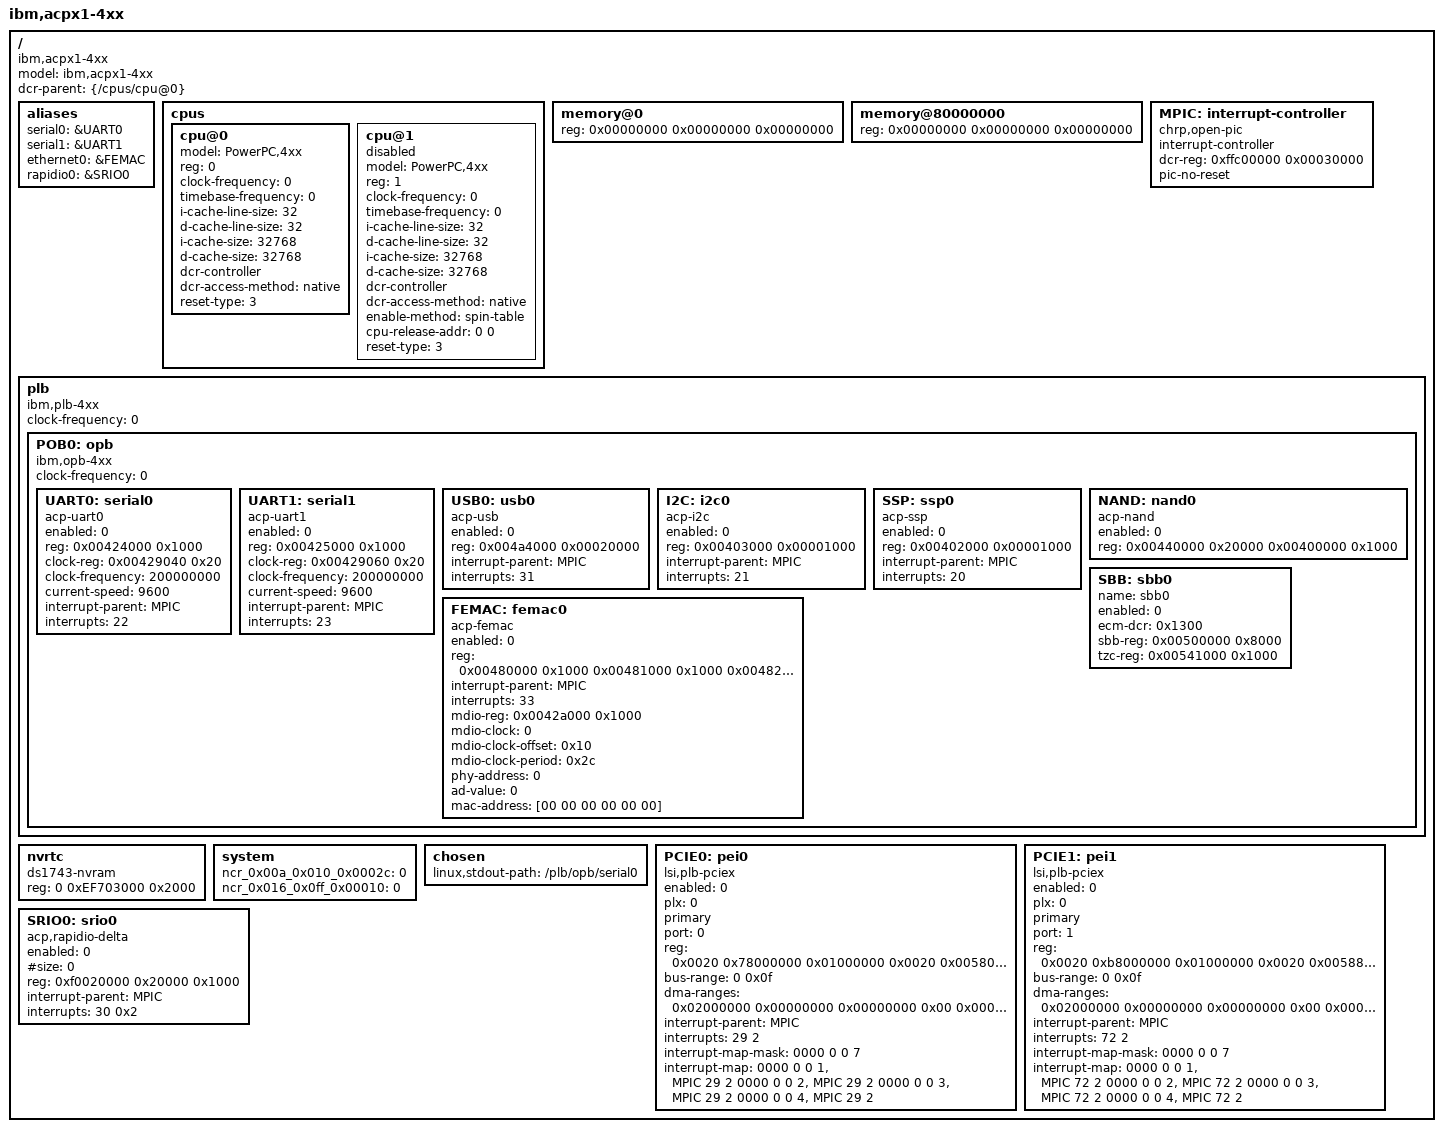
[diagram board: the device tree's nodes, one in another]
/*
 * Device Tree Source for LSI ACP25xx.
 *
 * Copyright 2013, LSI Corporation
 *
 * Based on earlier code:
 *     Copyright (c) 2009, 2006, 2007 IBM Corp.
 *     Josh Boyer <jwboyer@linux.vnet.ibm.com>, David Gibson <dwg@au1.ibm.com>
 *
 * This file is licensed under the terms of the GNU General Public
 * License version 2.  This program is licensed "as is" without
 * any warranty of any kind, whether express or implied.
 */

/dts-v1/;

/memreserve/ 0x00000000 0x00400000;

/ {
	#address-cells = <2>;
	#size-cells = <1>;
	model = "ibm,acpx1-4xx";
	compatible = "ibm,acpx1-4xx","ibm,47x-AMP";
	dcr-parent = <&{/cpus/cpu@0}>;

	aliases {
		serial0   = &UART0;
		serial1   = &UART1;
		ethernet0 = &FEMAC;
		rapidio0  = &SRIO0;
	};

	cpus {
		#address-cells = <1>;
		#size-cells = <0>;

		cpu@0 {
			device_type = "cpu";
			model = "PowerPC,4xx"; // real CPU changed in sim
			reg = <0>;
			clock-frequency = <0>; // filled in by U-Boot
			timebase-frequency = <0>; // filled in by U-Boot
			i-cache-line-size = <32>;
			d-cache-line-size = <32>;
			i-cache-size = <32768>;
			d-cache-size = <32768>;
			dcr-controller;
			dcr-access-method = "native";
			status = "ok";
			reset-type = <3>; // 1=core, 2=chip, 3=system (default)
		};

		cpu@1 {
			device_type = "cpu";
			model = "PowerPC,4xx"; // real CPU changed in sim
			reg = <1>;
			clock-frequency = <0>; // filled in by U-Boot
			timebase-frequency = <0>; // filled in by U-Boot
			i-cache-line-size = <32>;
			d-cache-line-size = <32>;
			i-cache-size = <32768>;
			d-cache-size = <32768>;
			dcr-controller;
			dcr-access-method = "native";
			status = "disabled";
			enable-method = "spin-table";
			cpu-release-addr = <0 0>; // Fixed by the boot loader
			reset-type = <3>; // 1=core, 2=chip, 3=system (default)
		};
	};

        memory@0 {
                device_type = "memory";
                reg = <0x00000000 0x00000000 0x00000000>; // filled in by U-Boot
        };

        memory@80000000 {
                device_type = "memory";
                reg = <0x00000000 0x00000000 0x00000000>; // filled in by U-Boot
        };

	MPIC: interrupt-controller {
		compatible = "chrp,open-pic";
		interrupt-controller;
		dcr-reg = <0xffc00000 0x00030000>;
		#address-cells = <0>;
		#size-cells = <0>;
		#interrupt-cells = <2>;
		pic-no-reset;
	};

	plb {
		/* Could be PLB6, doesn't matter */
		compatible = "ibm,plb-4xx", "ibm,plb4";
		#address-cells = <2>;
		#size-cells = <1>;
		ranges;
		clock-frequency = <0>; // Filled in by zImage

		POB0: opb {
			compatible = "ibm,opb-4xx", "ibm,opb";
			#address-cells = <1>;
			#size-cells = <1>;
			/* Wish there was a nicer way of specifying a full 32-bit
			   range */
			ranges = <0x00000000 0x00000020 0x00000000 0x80000000
				  0x80000000 0x00000020 0x80000000 0x80000000>;
			clock-frequency = <0>; // Filled in by zImage

			UART0: serial0 {
				device_type = "serial";
				compatible = "acp-uart0";
				enabled = <0>;
				reg = <0x00424000 0x1000>;
				clock-reg = <0x00429040 0x20>;
				clock-frequency = <200000000>;
				current-speed = <9600>;
				interrupt-parent = <&MPIC>;
				interrupts = <22>;
				/*interrupts = <23>;*/
			};

			UART1: serial1 {
				device_type = "serial";
				compatible = "acp-uart1";
				enabled = <0>;
				reg = <0x00425000 0x1000>;
				clock-reg = <0x00429060 0x20>;
				clock-frequency = <200000000>;
				current-speed = <9600>;
				interrupt-parent = <&MPIC>;
				interrupts = <23>;
			};

			USB0: usb0 {
				compatible = "acp-usb";
				enabled = <0>;
				reg = <0x004a4000 0x00020000>;
				interrupt-parent = <&MPIC>;
				interrupts = <31>;
			};

			I2C: i2c0 {
				compatible = "acp-i2c";
				enabled = <0>;
				reg = <0x00403000 0x00001000>;
				interrupt-parent = <&MPIC>;
				interrupts = <21>;
			};

			SSP: ssp0 {
				compatible = "acp-ssp";
				enabled = <0>;
				reg = <0x00402000 0x00001000>;
				interrupt-parent = <&MPIC>;
				interrupts = <20>;
			};

			NAND: nand0 {
				device_type = "nand";
				compatible = "acp-nand";
				enabled = <0>;
				reg = <0x00440000 0x20000
				       0x00400000 0x1000>;
			};

			FEMAC: femac0 {
				device_type = "network";
				compatible = "acp-femac";
				enabled = <0>;
				reg = <0x00480000 0x1000
				       0x00481000 0x1000
				       0x00482000 0x1000>;
				interrupt-parent = <&MPIC>;
				interrupts = <33>;
				/*interrupts = <32>;*/
				mdio-reg = <0x0042a000 0x1000>;
				// The following will get filled in by
				// the boot loader.
				mdio-clock = <0>;
				// Not filled in by U-Boot
				mdio-clock-offset = <0x10>;
				mdio-clock-period = <0x2c>;
				phy-address = <0>;
				ad-value = <0>;
				mac-address = [00 00 00 00 00 00];
			};

			SBB: sbb0 {
				name = "sbb0";
				enabled = <0>;
				ecm-dcr = <0x1300>;
				sbb-reg = <0x00500000 0x8000>;
				tzc-reg = <0x00541000 0x1000>;
			};
		};
	};


	nvrtc {
		compatible = "ds1743-nvram", "ds1743", "rtc-ds1743";
		reg = <0 0xEF703000 0x2000>;
	};

	system {
		ncr_0x00a_0x010_0x0002c = <0>; // filled in by the boot loader.
		ncr_0x016_0x0ff_0x00010 = <0>; // filled in by the boot loader.
	};

	chosen {
		linux,stdout-path = "/plb/opb/serial0";
	};

        PCIE0: pei0 {
                compatible = "lsi,plb-pciex";
                device_type = "pci";
                enabled = <0>;
                plx = <0>;
                primary;
                port = <0>;
                #interrupt-cells = <1>;
                #size-cells = <2>;
                #address-cells = <3>;
                /* config space access MPAGE7 registers*/
                reg = <0x0020 0x78000000 0x01000000
                       0x0020 0x00580000 0x00008000>;
                bus-range = <0 0x0f>;
                /* Outbound ranges */
                /* < <3-cell PCI addr> <2-cell CPU (PLB) addr> <2-cell size> > */
                ranges = <0x02000000 0x00000000 0xa0000000
                          0x20 0x40000000
                          0x00 0x10000000>;
                /* Inbound ranges */
                /* < <3-cell PCI addr> <2-cell CPU addr> <2-cell size> > */
                dma-ranges = <0x02000000 0x00000000 0x00000000
                              0x00 0x00000000
                              0x00 0x10000000>;
                    interrupt-parent = <&MPIC>;
                interrupts = <29 2>;
                interrupt-map-mask = <0000 0 0 7>;
                interrupt-map = <
                        /* <3-cell dev> <irq#> <prnt> <2-cell prnt IRQ/sense> */
                        0000 0 0 1 &MPIC 29 2
                        0000 0 0 2 &MPIC 29 2
                        0000 0 0 3 &MPIC 29 2
                        0000 0 0 4 &MPIC 29 2
                >;
        };

        PCIE1: pei1 {
                compatible = "lsi,plb-pciex";
                device_type = "pci";
                enabled = <0>;
                plx = <0>;
                primary;
                port = <1>;
                #interrupt-cells = <1>;
                #size-cells = <2>;
                #address-cells = <3>;
                /* config space access MPAGE7 registers*/
                reg = <0x0020 0xb8000000 0x01000000
                       0x0020 0x00588000 0x00008000>;
                bus-range = <0 0x0f>;
                /* Outbound ranges */
                /* < <3-cell PCI addr> <2-cell CPU (PLB) addr> <2-cell size> > */
                ranges = <0x02000000 0x00000000 0xb0000000
                          0x20 0x80000000
                          0x00 0x10000000>;
                /* Inbound ranges */
                /* < <3-cell PCI addr> <2-cell CPU addr> <2-cell size> > */
                dma-ranges = <0x02000000 0x00000000 0x00000000
                              0x00 0x00000000
                              0x00 0x10000000>;
                interrupt-parent = <&MPIC>;
                interrupts = <72 2>;
                interrupt-map-mask = <0000 0 0 7>;
                interrupt-map = <
                        /* <3-cell dev> <irq#> <prnt> <2-cell prnt IRQ/sense> */
                        0000 0 0 1 &MPIC 72 2
                        0000 0 0 2 &MPIC 72 2
                        0000 0 0 3 &MPIC 72 2
                        0000 0 0 4 &MPIC 72 2
                >;
        };

	SRIO0: srio0 {
		compatible = "acp,rapidio-delta";
                device_type = "rapidio";
		enabled = <0>;
		#size = <0>;    /* 0 = (256, small system)
				 * 1 = (65536, large system) */
		reg = <0xf0020000 0x20000 0x1000>; /* SRIO Conf region */
		interrupt-parent = <&MPIC>;
		interrupts = <30 0x2 /* NCP_INTR_MPIC_SRC_AXIS_SRIO */>;
	};
};
